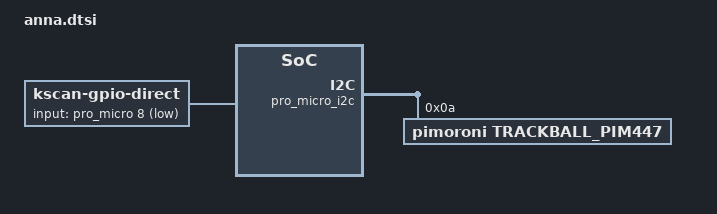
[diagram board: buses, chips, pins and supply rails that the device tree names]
/*
 * Copyright (c) 2020 The ZMK Contributors
 *
 * SPDX-License-Identifier: MIT
 */

#include <dt-bindings/zmk/matrix_transform.h>

/ {

	chosen {
		zmk,kscan = &kscan0;
		zmk,matrix_transform = &default_transform;
	};

	default_transform: keymap_transform_0 {
		compatible = "zmk,matrix-transform";
		columns = <1>;
		rows = <1>;
		map = <
		RC(0,0)
		>;
	};

	kscan0: kscan {
		compatible = "zmk,kscan-gpio-direct";
		label = "KSCAN";
		input-gpios = <&pro_micro  8 (GPIO_ACTIVE_LOW | GPIO_PULL_UP)>
		;
	};
};

&pro_micro_i2c {
    status = "okay";

    trackball_pim447@a {
        compatible = "pimoroni,trackball_pim447";
        reg = <0xa>;
        label = "TRACKBALL_PIM447";
    };
};
